# XHSC_HC32A052 register map
Vendor: XHSC Co.Ltd; Series: ARMCM4; File version: 1.2
CPU: CM0 r0p0, little endian, no MPU, no FPU, 3 interrupt priority bits
Registers are 32-bit, read-write, reset 0x0 unless marked. A register's access mark holds for its fields unless they carry their own. Offsets are from the block's base; [hi:lo] are bit positions; {n}, {i} and the like mark numbered series.

## EAU
Base 0x40021800
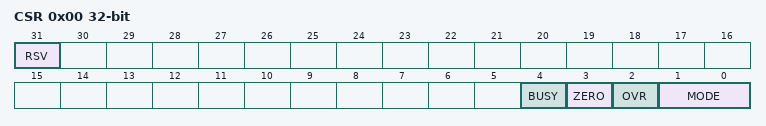
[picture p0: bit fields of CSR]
0x00 CSR (reset mask 0x3)
  [31] RSV ro, [4] BUSY ro, [3] ZERO ro, [2] OVR ro, [1:0] MODE
0x04 DIVIDEND
0x08 DIVISOR
0x0C QUOTIENT ro
0x10 REMAINDER ro

## FLASH
Base 0x40020000
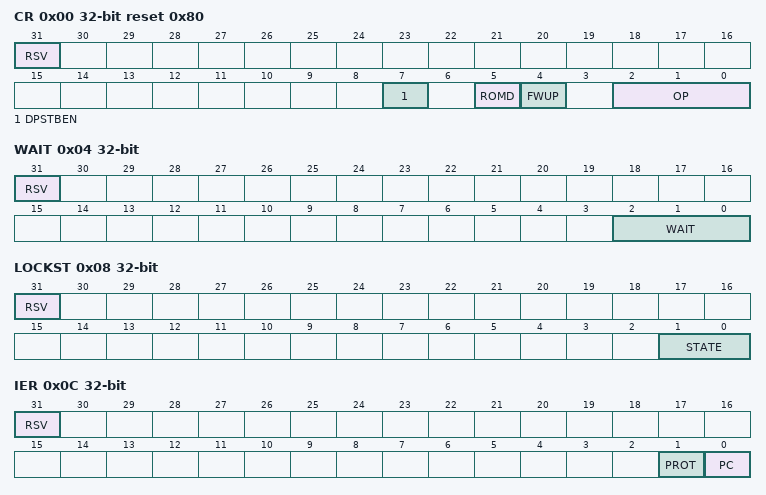
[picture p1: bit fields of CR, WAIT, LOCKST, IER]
0x00 CR reset 0x80 (reset mask 0xB7)
  [31] RSV ro, [7] DPSTBEN, [5] ROMD, [4] FWUP, [2:0] OP
0x04 WAIT (reset mask 0x7)
  [31] RSV ro, [2:0] WAIT
0x08 LOCKST ro (reset mask 0x3)
  [31] RSV, [1:0] STATE
0x0C IER (reset mask 0x3)
  [31] RSV ro, [1] PROT, [0] PC
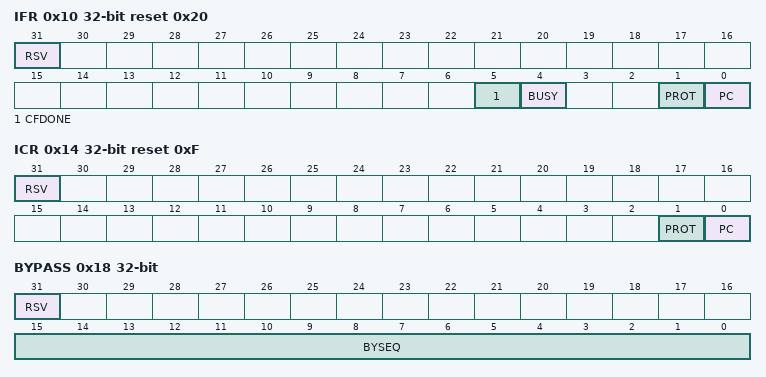
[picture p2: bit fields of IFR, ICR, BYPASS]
0x10 IFR ro reset 0x20 (reset mask 0x33)
  [31] RSV, [5] CFDONE, [4] BUSY rw, [1] PROT, [0] PC
0x14 ICR reset 0xF (reset mask 0x3)
  [31] RSV ro, [1] PROT, [0] PC
0x18 BYPASS (reset mask 0xFFFF)
  [31] RSV ro, [15:0] BYSEQ
0x30 SLOCK0
  [31:0] SLOCK
0x34 SLOCK1
  [31:0] SLOCK

## GPIOA — desc GPIO
Base 0x40020C00
Same registers: GPIOB 0x40021C00, GPIOC 0x40022000, GPIOD 0x40022400
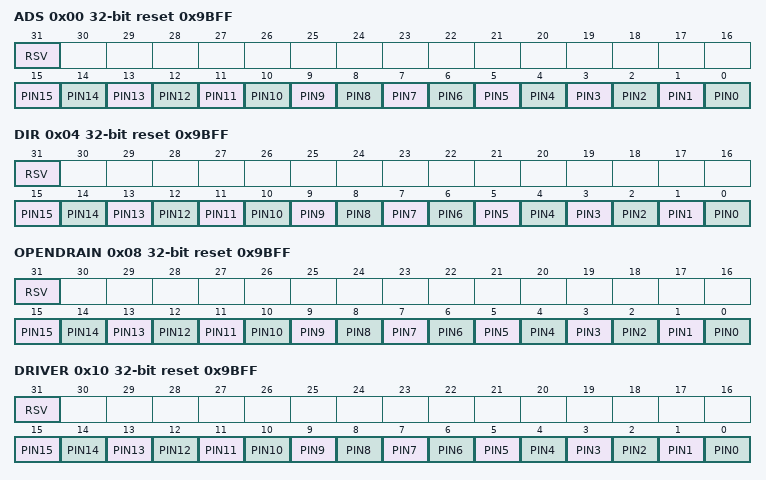
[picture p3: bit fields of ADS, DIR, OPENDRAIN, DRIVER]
0x00 ADS reset 0x9BFF (reset mask 0xFFFF)
  [31] RSV, [n] PIN{n} (n=0..15)
0x04 DIR reset 0x9BFF (reset mask 0xFFFF)
  [31] RSV, [n] PIN{n} (n=0..15)
0x08 OPENDRAIN reset 0x9BFF (reset mask 0xFFFF)
  [31] RSV, [n] PIN{n} (n=0..15)
0x10 DRIVER reset 0x9BFF (reset mask 0xFFFF)
  [31] RSV, [n] PIN{n} (n=0..15)
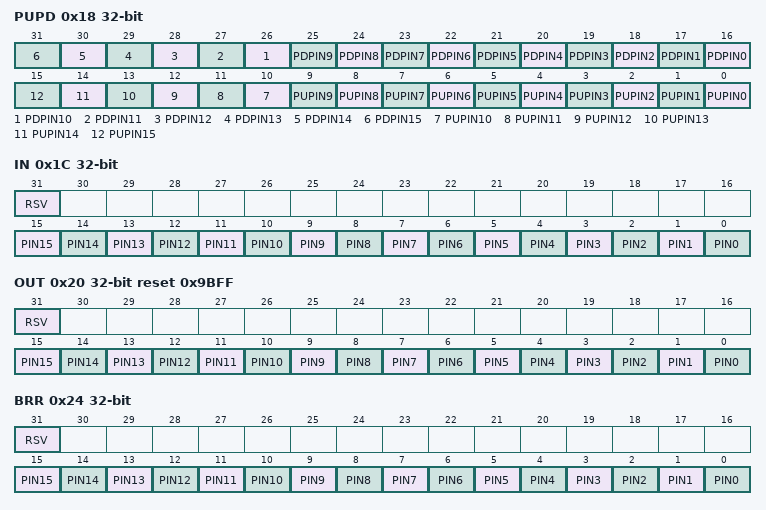
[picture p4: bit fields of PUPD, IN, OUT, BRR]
0x18 PUPD
  [n+16] PDPIN{n} (n=0..15), [n] PUPIN{n} (n=0..15)
0x1C IN ro (reset mask 0xFFFF)
  [31] RSV, [n] PIN{n} (n=0..15)
0x20 OUT reset 0x9BFF (reset mask 0xFFFF)
  [31] RSV, [n] PIN{n} (n=0..15)
0x24 BRR wo (reset mask 0xFFFF)
  [31] RSV, [n] PIN{n} (n=0..15)
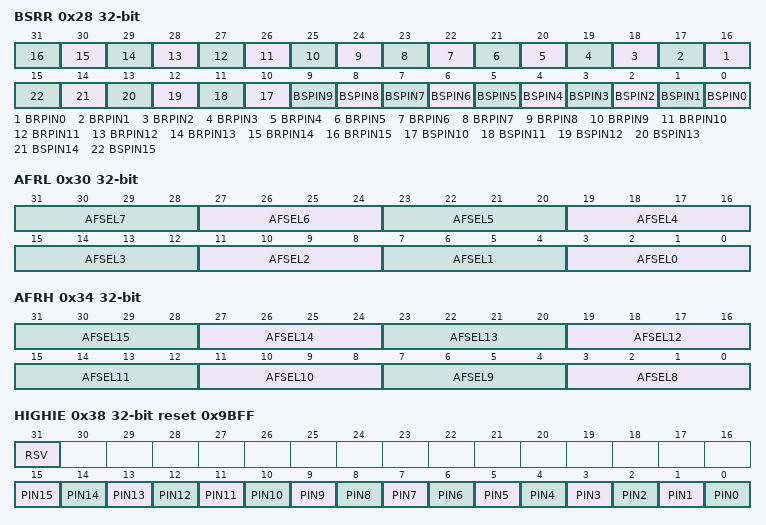
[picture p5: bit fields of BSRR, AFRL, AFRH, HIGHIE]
0x28 BSRR wo
  [n+16] BRPIN{n} (n=0..15), [n] BSPIN{n} (n=0..15)
0x30 AFRL
  [4n+3:4n] AFSEL{n} (n=0..7)
0x34 AFRH
  [4n-29:4n-32] AFSEL{n} (n=8..15)
0x38 HIGHIE reset 0x9BFF (reset mask 0xFFFF)
  [31] RSV, [n] PIN{n} (n=0..15)
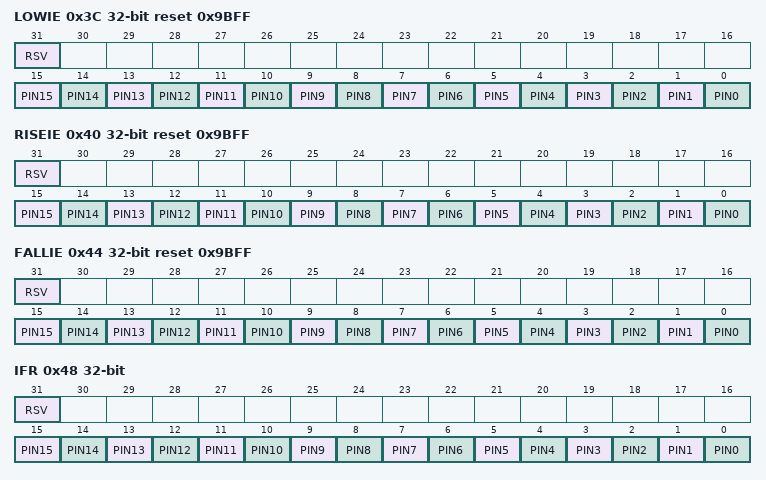
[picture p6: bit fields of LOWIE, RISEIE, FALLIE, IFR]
0x3C LOWIE reset 0x9BFF (reset mask 0xFFFF)
  [31] RSV, [n] PIN{n} (n=0..15)
0x40 RISEIE reset 0x9BFF (reset mask 0xFFFF)
  [31] RSV, [n] PIN{n} (n=0..15)
0x44 FALLIE reset 0x9BFF (reset mask 0xFFFF)
  [31] RSV, [n] PIN{n} (n=0..15)
0x48 IFR ro (reset mask 0xFFFF)
  [31] RSV, [n] PIN{n} (n=0..15)
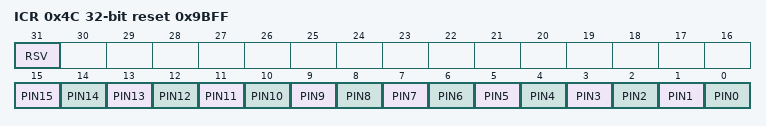
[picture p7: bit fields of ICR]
0x4C ICR reset 0x9BFF (reset mask 0xFFFF)
  [31] RSV, [n] PIN{n} (n=0..15)

## GPIOAUX
Base 0x40002000
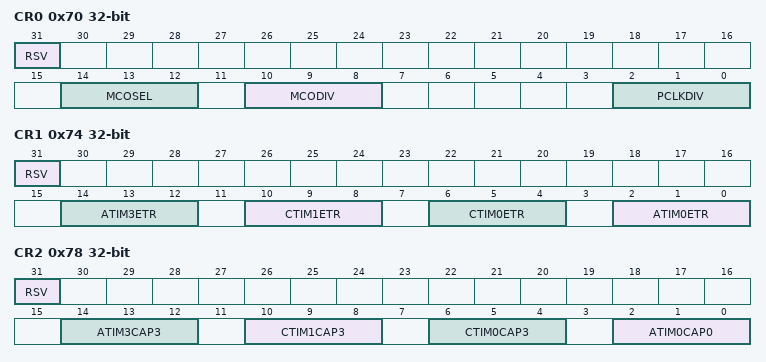
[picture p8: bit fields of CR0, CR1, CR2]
0x70 CR0 (reset mask 0x7F)
  [31] RSV, [14:12] MCOSEL, [10:8] MCODIV, [2:0] PCLKDIV
0x74 CR1 (reset mask 0x7F)
  [31] RSV, [14:12] ATIM3ETR, [10:8] CTIM1ETR, [6:4] CTIM0ETR, [2:0] ATIM0ETR
0x78 CR2 (reset mask 0x7F)
  [31] RSV ro, [14:12] ATIM3CAP3, [10:8] CTIM1CAP3, [6:4] CTIM0CAP3, [2:0] ATIM0CAP0

## GTIM0 — desc GTIM
Base 0x40001800; alternate view of BTIM0
Same registers: GTIM1 0x40001C00 (alternate view of BTIM3)
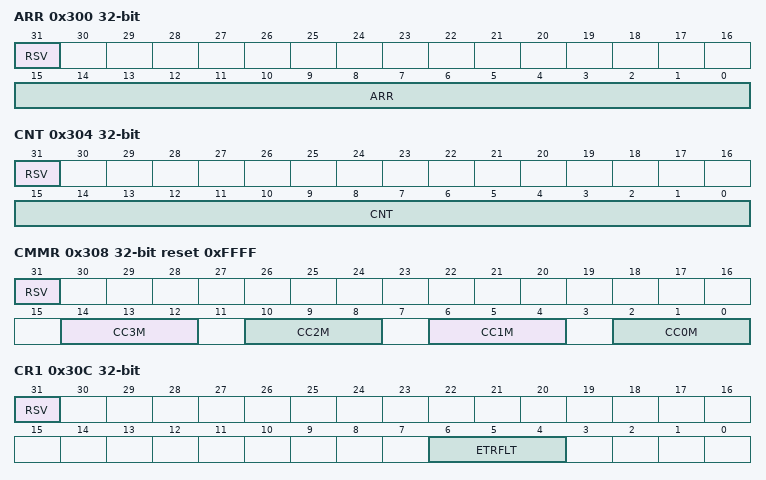
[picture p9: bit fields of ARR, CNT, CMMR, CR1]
0x300 ARR (reset mask 0xFFFF)
  [31] RSV, [15:0] ARR
0x304 CNT (reset mask 0xFFFF)
  [31] RSV, [15:0] CNT
0x308 CMMR reset 0xFFFF (reset mask 0x7777)
  [31] RSV, [4n+2:4n] CC{n}M (n=0..3)
0x30C CR1 (reset mask 0x70)
  [31] RSV, [6:4] ETRFLT
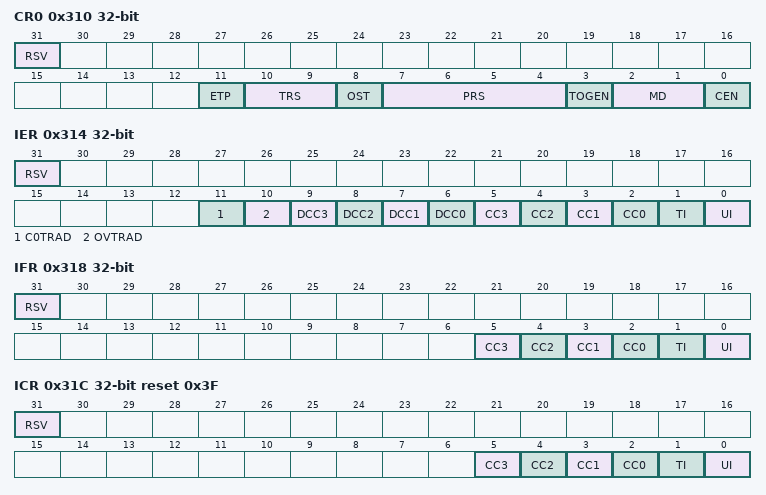
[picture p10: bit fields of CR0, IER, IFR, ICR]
0x310 CR0 (reset mask 0xFFF)
  [31] RSV, [11] ETP, [10:9] TRS, [8] OST, [7:4] PRS, [3] TOGEN, [2:1] MD, [0] CEN
0x314 IER (reset mask 0xFFF)
  [31] RSV, [11] C0TRAD, [10] OVTRAD, [n+6] DCC{n} (n=0..3), [n+2] CC{n} (n=0..3), [1] TI, [0] UI
0x318 IFR (reset mask 0x3F)
  [31] RSV, [n+2] CC{n} (n=0..3), [1] TI, [0] UI
0x31C ICR reset 0x3F (reset mask 0x3F)
  [31] RSV, [n+2] CC{n} (n=0..3), [1] TI, [0] UI
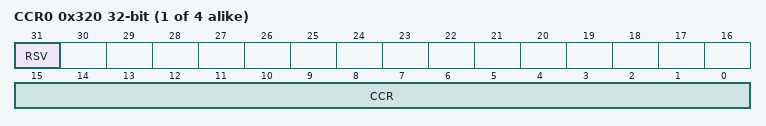
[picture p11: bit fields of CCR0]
{0x320+4i} CCR{i} (reset mask 0xFFFF) (i=0..3)
  [31] RSV, [15:0] CCR

## I2C0 — desc I2C
Base 0x40000400
Same registers: I2C1 0x40004400
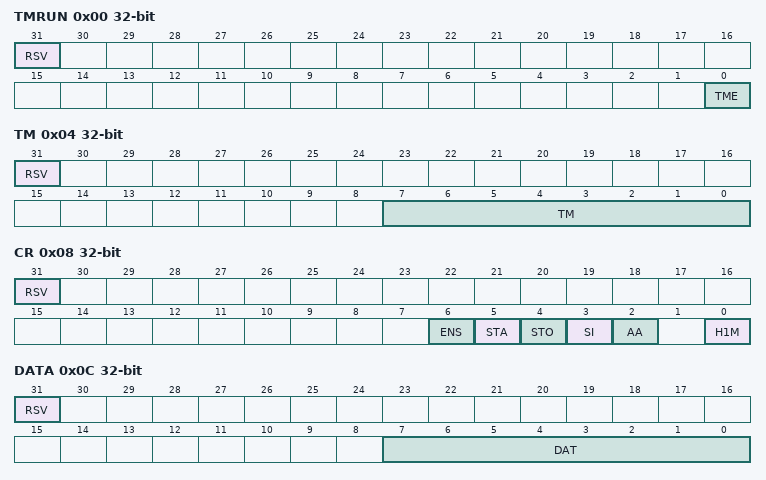
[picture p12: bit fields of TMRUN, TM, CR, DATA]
0x00 TMRUN (reset mask 0x1)
  [31] RSV, [0] TME
0x04 TM (reset mask 0xFF)
  [31] RSV, [7:0] TM
0x08 CR (reset mask 0x7D)
  [31] RSV, [6] ENS, [5] STA, [4] STO, [3] SI, [2] AA, [0] H1M
0x0C DATA (reset mask 0xFF)
  [31] RSV, [7:0] DAT
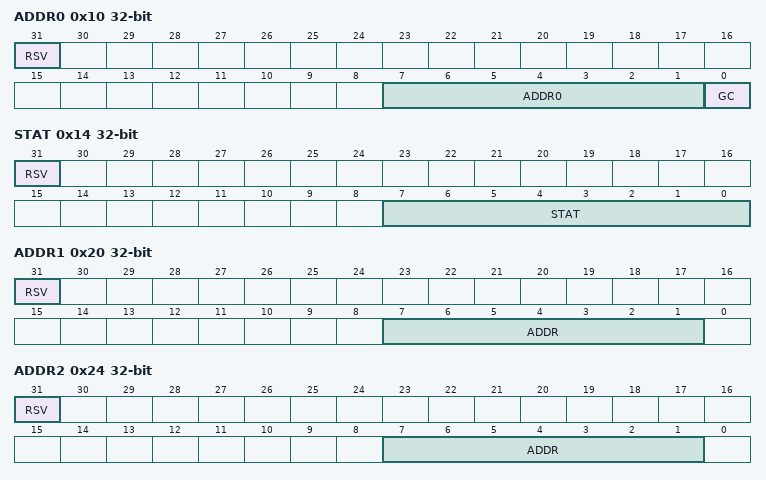
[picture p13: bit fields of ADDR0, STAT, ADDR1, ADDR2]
0x10 ADDR0 (reset mask 0xFF)
  [31] RSV, [7:1] ADDR0, [0] GC
0x14 STAT ro (reset mask 0xFF)
  [31] RSV, [7:0] STAT
0x20 ADDR1 (reset mask 0xFF)
  [31] RSV, [7:1] ADDR
0x24 ADDR2 (reset mask 0xFF)
  [31] RSV, [7:1] ADDR
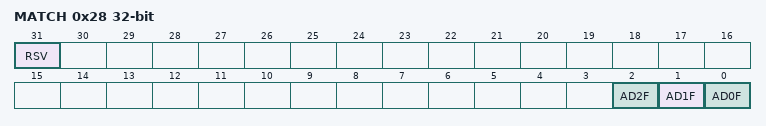
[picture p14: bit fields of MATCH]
0x28 MATCH ro (reset mask 0xFF)
  [31] RSV, [2] AD2F, [1] AD1F, [0] AD0F
